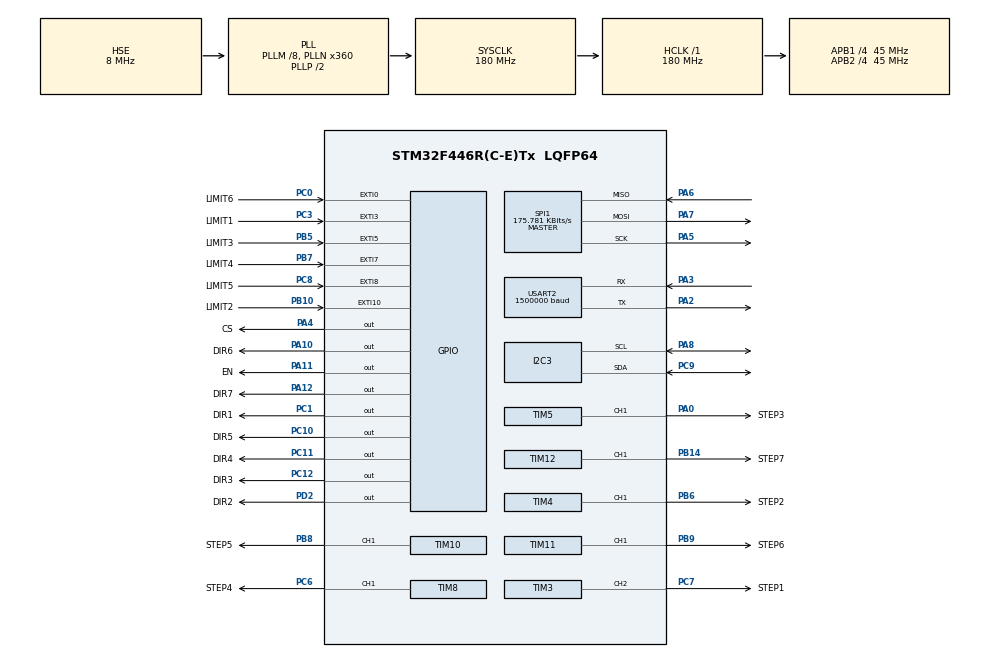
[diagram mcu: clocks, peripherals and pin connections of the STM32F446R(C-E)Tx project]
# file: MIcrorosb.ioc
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Dma.I2C3_RX.2.Direction=DMA_PERIPH_TO_MEMORY
Dma.I2C3_RX.2.FIFOMode=DMA_FIFOMODE_DISABLE
Dma.I2C3_RX.2.Instance=DMA1_Stream1
Dma.I2C3_RX.2.MemDataAlignment=DMA_MDATAALIGN_BYTE
Dma.I2C3_RX.2.MemInc=DMA_MINC_ENABLE
Dma.I2C3_RX.2.Mode=DMA_NORMAL
Dma.I2C3_RX.2.PeriphDataAlignment=DMA_PDATAALIGN_BYTE
Dma.I2C3_RX.2.PeriphInc=DMA_PINC_DISABLE
Dma.I2C3_RX.2.Priority=DMA_PRIORITY_LOW
Dma.I2C3_TX.3.Direction=DMA_MEMORY_TO_PERIPH
Dma.I2C3_TX.3.FIFOMode=DMA_FIFOMODE_DISABLE
Dma.I2C3_TX.3.Instance=DMA1_Stream4
Dma.I2C3_TX.3.MemDataAlignment=DMA_MDATAALIGN_BYTE
Dma.I2C3_TX.3.MemInc=DMA_MINC_ENABLE
Dma.I2C3_TX.3.Mode=DMA_NORMAL
Dma.I2C3_TX.3.PeriphDataAlignment=DMA_PDATAALIGN_BYTE
Dma.I2C3_TX.3.PeriphInc=DMA_PINC_DISABLE
Dma.I2C3_TX.3.Priority=DMA_PRIORITY_LOW
Dma.Request0=USART2_RX
Dma.Request1=USART2_TX
Dma.Request2=I2C3_RX
Dma.Request3=I2C3_TX
Dma.USART2_RX.0.Direction=DMA_PERIPH_TO_MEMORY
Dma.USART2_RX.0.FIFOMode=DMA_FIFOMODE_DISABLE
Dma.USART2_RX.0.Instance=DMA1_Stream5
Dma.USART2_RX.0.MemDataAlignment=DMA_MDATAALIGN_BYTE
Dma.USART2_RX.0.MemInc=DMA_MINC_ENABLE
Dma.USART2_RX.0.Mode=DMA_CIRCULAR
Dma.USART2_RX.0.PeriphDataAlignment=DMA_PDATAALIGN_BYTE
Dma.USART2_RX.0.PeriphInc=DMA_PINC_DISABLE
Dma.USART2_RX.0.Priority=DMA_PRIORITY_VERY_HIGH
Dma.USART2_TX.1.Direction=DMA_MEMORY_TO_PERIPH
Dma.USART2_TX.1.FIFOMode=DMA_FIFOMODE_DISABLE
Dma.USART2_TX.1.Instance=DMA1_Stream6
Dma.USART2_TX.1.MemDataAlignment=DMA_MDATAALIGN_BYTE
Dma.USART2_TX.1.MemInc=DMA_MINC_ENABLE
Dma.USART2_TX.1.Mode=DMA_NORMAL
Dma.USART2_TX.1.PeriphDataAlignment=DMA_PDATAALIGN_BYTE
Dma.USART2_TX.1.PeriphInc=DMA_PINC_DISABLE
Dma.USART2_TX.1.Priority=DMA_PRIORITY_VERY_HIGH
FREERTOS.Tasks01=ros_task,24,3000,StartRosTask,Default,NULL,Dynamic,NULL,NULL;motor_task,8,500,StartMotorTask,Default,NULL,Dynamic,NULL,NULL;sensorread_task,8,500,StartSensorTask,Default,NULL,Dynamic,NULL,NULL
FREERTOS.configMINIMAL_STACK_SIZE=500
FREERTOS.configTOTAL_HEAP_SIZE=32000
I2C3.I2C_Mode=I2C_Fast
Mcu.Family=STM32F4
Mcu.Name=STM32F446R(C-E)Tx
Mcu.Package=LQFP64
NVIC.DMA1_Stream1_IRQn=true\:5\:0\:false\:false\:true\:true\:false\:true\:true
NVIC.DMA1_Stream4_IRQn=true\:5\:0\:false\:false\:true\:true\:false\:true\:true
NVIC.DMA1_Stream5_IRQn=true\:5\:0\:false\:false\:true\:true\:false\:true\:true
NVIC.DMA1_Stream6_IRQn=true\:5\:0\:false\:false\:true\:true\:false\:true\:true
NVIC.EXTI0_IRQn=true\:5\:0\:false\:false\:true\:true\:true\:true\:true
NVIC.EXTI15_10_IRQn=true\:5\:0\:false\:false\:true\:true\:true\:true\:true
NVIC.EXTI3_IRQn=true\:5\:0\:false\:false\:true\:true\:true\:true\:true
NVIC.EXTI9_5_IRQn=true\:5\:0\:false\:false\:true\:true\:true\:true\:true
NVIC.I2C3_ER_IRQn=true\:5\:0\:false\:false\:true\:true\:true\:true\:true
NVIC.I2C3_EV_IRQn=true\:5\:0\:false\:false\:true\:true\:true\:true\:true
NVIC.PriorityGroup=NVIC_PRIORITYGROUP_4
NVIC.TIM1_TRG_COM_TIM11_IRQn=true\:5\:0\:false\:false\:true\:true\:true\:true\:true
NVIC.TIM1_UP_TIM10_IRQn=true\:15\:0\:false\:false\:true\:false\:false\:true\:true
NVIC.TIM3_IRQn=true\:5\:0\:false\:false\:true\:true\:true\:true\:true
NVIC.TIM4_IRQn=true\:5\:0\:false\:false\:true\:true\:true\:true\:true
NVIC.TIM5_IRQn=true\:5\:0\:false\:false\:true\:true\:true\:true\:true
NVIC.TIM7_IRQn=true\:5\:0\:false\:false\:true\:true\:true\:true\:true
NVIC.TIM8_BRK_TIM12_IRQn=true\:5\:0\:false\:false\:true\:true\:true\:true\:true
NVIC.TIM8_UP_TIM13_IRQn=true\:5\:0\:false\:false\:true\:true\:true\:true\:true
NVIC.TimeBase=TIM1_UP_TIM10_IRQn
NVIC.TimeBaseIP=TIM1
NVIC.USART2_IRQn=true\:5\:0\:false\:false\:true\:true\:true\:true\:true
PA0-WKUP.GPIO_Label=STEP3
PA0-WKUP.GPIO_Speed=GPIO_SPEED_FREQ_VERY_HIGH
PA0-WKUP.Signal=S_TIM5_CH1
PA10.GPIO_Label=DIR6
PA10.Signal=GPIO_Output
PA11.GPIO_Label=EN
PA11.Signal=GPIO_Output
PA12.GPIO_Label=DIR7
PA12.Signal=GPIO_Output
PA2.Mode=Asynchronous
PA2.Signal=USART2_TX
PA3.Mode=Asynchronous
PA3.Signal=USART2_RX
PA4.GPIO_Label=CS
PA4.GPIO_Speed=GPIO_SPEED_FREQ_VERY_HIGH
PA4.PinState=GPIO_PIN_SET
PA4.Signal=GPIO_Output
PA5.Mode=Full_Duplex_Master
PA5.Signal=SPI1_SCK
PA6.Mode=Full_Duplex_Master
PA6.Signal=SPI1_MISO
PA7.Mode=Full_Duplex_Master
PA7.Signal=SPI1_MOSI
PA8.GPIO_Pu=GPIO_PULLUP
PA8.Mode=I2C
PA8.Signal=I2C3_SCL
PB10.GPIO_Label=LIMIT2
PB10.GPIO_ModeDefaultEXTI=GPIO_MODE_IT_RISING
PB10.GPIO_PuPd=GPIO_NOPULL
PB10.Signal=GPXTI10
PB14.GPIO_Label=STEP7
PB14.GPIO_Speed=GPIO_SPEED_FREQ_VERY_HIGH
PB14.Signal=S_TIM12_CH1
PB5.GPIO_Label=LIMIT3
PB5.GPIO_ModeDefaultEXTI=GPIO_MODE_IT_RISING
PB5.GPIO_PuPd=GPIO_NOPULL
PB5.Signal=GPXTI5
PB6.GPIO_Label=STEP2
PB6.GPIO_ModeDefaultPP=GPIO_MODE_AF_PP
PB6.GPIO_PuPd=GPIO_PULLDOWN
PB6.GPIO_Speed=GPIO_SPEED_FREQ_VERY_HIGH
PB6.Signal=S_TIM4_CH1
PB7.GPIO_Label=LIMIT4
PB7.GPIO_PuPd=GPIO_PULLDOWN
PB7.Signal=GPXTI7
PB8.GPIO_Label=STEP5
PB8.GPIO_PuPd=GPIO_PULLDOWN
PB8.GPIO_Speed=GPIO_SPEED_FREQ_VERY_HIGH
PB8.Signal=S_TIM10_CH1
PB9.GPIO_Label=STEP6
PB9.GPIO_Speed=GPIO_SPEED_FREQ_VERY_HIGH
PB9.Signal=S_TIM11_CH1
PC0.GPIO_Label=LIMIT6
PC0.GPIO_PuPd=GPIO_PULLDOWN
PC0.Signal=GPXTI0
PC1.GPIO_Label=DIR1
PC1.Signal=GPIO_Output
PC10.GPIO_Label=DIR5
PC10.Signal=GPIO_Output
PC11.GPIO_Label=DIR4
PC11.Signal=GPIO_Output
PC12.GPIO_Label=DIR3
PC12.Signal=GPIO_Output
PC3.GPIO_Label=LIMIT1
PC3.GPIO_PuPd=GPIO_PULLDOWN
PC3.Signal=GPXTI3
PC6.GPIO_Label=STEP4
PC6.GPIO_Speed=GPIO_SPEED_FREQ_VERY_HIGH
PC6.Signal=S_TIM8_CH1
PC7.GPIO_Label=STEP1
PC7.GPIO_Speed=GPIO_SPEED_FREQ_VERY_HIGH
PC7.Signal=S_TIM3_CH2
PC8.GPIO_Label=LIMIT5
PC8.GPIO_ModeDefaultEXTI=GPIO_MODE_IT_RISING
PC8.GPIO_PuPd=GPIO_NOPULL
PC8.Signal=GPXTI8
PC9.GPIO_Pu=GPIO_PULLUP
PC9.Mode=I2C
PC9.Signal=I2C3_SDA
PD2.GPIO_Label=DIR2
PD2.Signal=GPIO_Output
PH0-OSC_IN.Mode=HSE-External-Oscillator
PH0-OSC_IN.Signal=RCC_OSC_IN
PH1-OSC_OUT.Mode=HSE-External-Oscillator
PH1-OSC_OUT.Signal=RCC_OSC_OUT
ProjectManager.HeapSize=0x200
ProjectManager.StackSize=0x400
ProjectManager.TargetToolchain=STM32CubeIDE
RCC.AHBFreq_Value=180000000
RCC.APB1CLKDivider=RCC_HCLK_DIV4
RCC.APB1Freq_Value=45000000
RCC.APB1TimFreq_Value=90000000
RCC.APB2CLKDivider=RCC_HCLK_DIV4
RCC.APB2Freq_Value=45000000
RCC.APB2TimFreq_Value=90000000
RCC.CortexFreq_Value=180000000
RCC.HCLKFreq_Value=180000000
RCC.HSE_VALUE=8000000
RCC.PLLM=8
RCC.PLLN=360
RCC.PLLSourceVirtual=RCC_PLLSOURCE_HSE
RCC.SYSCLKFreq_VALUE=180000000
RCC.SYSCLKSource=RCC_SYSCLKSOURCE_PLLCLK
RCC.USBFreq_Value=180000000
RCC.VCOOutputFreq_Value=360000000
SH.S_TIM10_CH1.0=TIM10_CH1,PWM Generation1 CH1
SH.S_TIM11_CH1.0=TIM11_CH1,PWM Generation1 CH1
SH.S_TIM12_CH1.0=TIM12_CH1,PWM Generation1 CH1
SH.S_TIM3_CH2.0=TIM3_CH2,PWM Generation2 CH2
SH.S_TIM4_CH1.0=TIM4_CH1,PWM Generation1 CH1
SH.S_TIM5_CH1.0=TIM5_CH1,PWM Generation1 CH1
SH.S_TIM8_CH1.0=TIM8_CH1,PWM Generation1 CH1
SPI1.BaudRatePrescaler=SPI_BAUDRATEPRESCALER_256
SPI1.CalculateBaudRate=175.781 KBits/s
SPI1.Direction=SPI_DIRECTION_2LINES
SPI1.Mode=SPI_MODE_MASTER
SPI1.VirtualType=VM_MASTER
TIM10.AutoReloadPreload=TIM_AUTORELOAD_PRELOAD_ENABLE
TIM10.Channel=TIM_CHANNEL_1
TIM10.ClockDivision=TIM_CLOCKDIVISION_DIV1
TIM10.OCFastMode_PWM=TIM_OCFAST_DISABLE
TIM10.Period=999
TIM10.Prescaler=44
TIM11.AutoReloadPreload=TIM_AUTORELOAD_PRELOAD_ENABLE
TIM11.Channel=TIM_CHANNEL_1
TIM11.ClockDivision=TIM_CLOCKDIVISION_DIV1
TIM11.OCFastMode_PWM=TIM_OCFAST_DISABLE
TIM11.Period=999
TIM11.Prescaler=44
TIM12.AutoReloadPreload=TIM_AUTORELOAD_PRELOAD_ENABLE
TIM12.Channel-PWM\ Generation1\ CH1=TIM_CHANNEL_1
TIM12.ClockDivision=TIM_CLOCKDIVISION_DIV1
TIM12.OCFastMode_PWM-PWM\ Generation1\ CH1=TIM_OCFAST_ENABLE
TIM12.Period=999
TIM12.Prescaler=44
TIM3.AutoReloadPreload=TIM_AUTORELOAD_PRELOAD_ENABLE
TIM3.Channel-PWM\ Generation2\ CH2=TIM_CHANNEL_2
TIM3.OC2Preload_PWM=ENABLE
TIM3.OCFastMode_PWM-PWM\ Generation2\ CH2=TIM_OCFAST_ENABLE
TIM3.Period=999
TIM3.Prescaler=44
TIM3.Pulse-PWM\ Generation2\ CH2=0
TIM4.AutoReloadPreload=TIM_AUTORELOAD_PRELOAD_ENABLE
TIM4.Channel-PWM\ Generation1\ CH1=TIM_CHANNEL_1
TIM4.OCFastMode_PWM-PWM\ Generation1\ CH1=TIM_OCFAST_ENABLE
TIM4.Period=89
TIM4.Prescaler=44
TIM4.Pulse-PWM\ Generation1\ CH1=10
TIM5.AutoReloadPreload=TIM_AUTORELOAD_PRELOAD_ENABLE
TIM5.Channel-PWM\ Generation1\ CH1=TIM_CHANNEL_1
TIM5.Period=999
TIM5.Prescaler=44
TIM7.Period=49
TIM7.Prescaler=89
TIM8.AutoReloadPreload=TIM_AUTORELOAD_PRELOAD_ENABLE
TIM8.Channel-PWM\ Generation1\ CH1=TIM_CHANNEL_1
TIM8.ClockDivision=TIM_CLOCKDIVISION_DIV1
TIM8.OCFastMode_PWM-PWM\ Generation1\ CH1=TIM_OCFAST_DISABLE
TIM8.Period=999
TIM8.Prescaler=44
USART2.BaudRate=1500000
USART2.OverSampling=UART_OVERSAMPLING_16
USART2.VirtualMode=VM_ASYNC
VP_FREERTOS_VS_CMSIS_V2.Mode=CMSIS_V2
VP_SYS_VS_tim1.Mode=TIM1
VP_TIM10_VS_ClockSourceINT.Mode=Enable_Timer
VP_TIM11_VS_ClockSourceINT.Mode=Enable_Timer
VP_TIM7_VS_ClockSourceINT.Mode=Enable_Timer
board=custom

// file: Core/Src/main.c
/* USER CODE BEGIN Header */
/**
 ******************************************************************************
 * @file           : main.c
 * @brief          : Main program body
 ******************************************************************************
 * @attention
 *
 * Copyright (c) 2025 STMicroelectronics.
 * All rights reserved.
 *
 * This software is licensed under terms that can be found in the LICENSE file
 * in the root directory of this software component.
 * If no LICENSE file comes with this software, it is provided AS-IS.
 *
 ******************************************************************************
 */
/* USER CODE END Header */
#include "main.h"
#include "cmsis_os.h"
#include "dma.h"
#include "i2c.h"
#include "spi.h"
#include "tim.h"
#include "usart.h"
#include "gpio.h"

void SystemClock_Config(void);
void MX_FREERTOS_Init(void);
/* USER CODE BEGIN PFP */
void MotorTimerISR(TIM_HandleTypeDef *htim);
/* USER CODE END PFP */

/* USER CODE BEGIN 0 */

/* --- Minimal transport --- */
/* USER CODE END 0 */

int main(void)
{

  /* MCU Configuration--------------------------------------------------------*/

  /* Reset of all peripherals, Initializes the Flash interface and the Systick. */
  HAL_Init();

  /* Configure the system clock */
  SystemClock_Config();

  /* Initialize all configured peripherals */
  MX_GPIO_Init();
  MX_DMA_Init();
  MX_USART2_UART_Init();
  MX_SPI1_Init();
  MX_TIM4_Init();
  MX_TIM5_Init();
  MX_TIM8_Init();
  MX_TIM10_Init();
  MX_TIM11_Init();
  MX_TIM12_Init();
  MX_I2C3_Init();
  MX_TIM3_Init();
  MX_TIM7_Init();
  /* USER CODE BEGIN 2 */
  HAL_GPIO_WritePin(EN_GPIO_Port, EN_Pin, 0);

  /* Start S-curve tick timer (runs at 20kHz indefinitely) */
  extern void SCurve_Tick_Start(void);
  SCurve_Tick_Start();
  /* USER CODE END 2 */

  /* Init scheduler */
  osKernelInitialize();  /* Call init function for freertos objects (in cmsis_os2.c) */
  MX_FREERTOS_Init();

  /* Start scheduler */
  osKernelStart();

  /* We should never get here as control is now taken by the scheduler */

  /* Infinite loop */
  while (1) {

  }
}

void SystemClock_Config(void)
{
  RCC_OscInitTypeDef RCC_OscInitStruct = {0};
  RCC_ClkInitTypeDef RCC_ClkInitStruct = {0};

  /** Configure the main internal regulator output voltage
  */
  __HAL_RCC_PWR_CLK_ENABLE();
  __HAL_PWR_VOLTAGESCALING_CONFIG(PWR_REGULATOR_VOLTAGE_SCALE1);

  /** Initializes the RCC Oscillators according to the specified parameters
  * in the RCC_OscInitTypeDef structure.
  */
  RCC_OscInitStruct.OscillatorType = RCC_OSCILLATORTYPE_HSE;
  RCC_OscInitStruct.HSEState = RCC_HSE_ON;
  RCC_OscInitStruct.PLL.PLLState = RCC_PLL_ON;
  RCC_OscInitStruct.PLL.PLLSource = RCC_PLLSOURCE_HSE;
  RCC_OscInitStruct.PLL.PLLM = 8;
  RCC_OscInitStruct.PLL.PLLN = 360;
  RCC_OscInitStruct.PLL.PLLP = RCC_PLLP_DIV2;
  RCC_OscInitStruct.PLL.PLLQ = 2;
  RCC_OscInitStruct.PLL.PLLR = 2;
  if (HAL_RCC_OscConfig(&RCC_OscInitStruct) != HAL_OK)
  {
    Error_Handler();
  }

  /** Activate the Over-Drive mode
  */
  if (HAL_PWREx_EnableOverDrive() != HAL_OK)
  {
    Error_Handler();
  }

  /** Initializes the CPU, AHB and APB buses clocks
  */
  RCC_ClkInitStruct.ClockType = RCC_CLOCKTYPE_HCLK|RCC_CLOCKTYPE_SYSCLK
                              |RCC_CLOCKTYPE_PCLK1|RCC_CLOCKTYPE_PCLK2;
  RCC_ClkInitStruct.SYSCLKSource = RCC_SYSCLKSOURCE_PLLCLK;
  RCC_ClkInitStruct.AHBCLKDivider = RCC_SYSCLK_DIV1;
  RCC_ClkInitStruct.APB1CLKDivider = RCC_HCLK_DIV4;
  RCC_ClkInitStruct.APB2CLKDivider = RCC_HCLK_DIV4;

  if (HAL_RCC_ClockConfig(&RCC_ClkInitStruct, FLASH_LATENCY_5) != HAL_OK)
  {
    Error_Handler();
  }
}

void HAL_TIM_PeriodElapsedCallback(TIM_HandleTypeDef *htim)
{
  if (htim->Instance == TIM1)
  {
    HAL_IncTick();
  }
  /* USER CODE BEGIN Callback 1 */
  else {
    MotorTimerISR(htim);
  }
  /* USER CODE END Callback 1 */
}

void Error_Handler(void)
{
  __disable_irq();
  while (1) {
  }
}
#ifdef USE_FULL_ASSERT
/**
  * @brief  Reports the name of the source file and the source line number
  *         where the assert_param error has occurred.
  * @param  file: pointer to the source file name
  * @param  line: assert_param error line source number
  * @retval None
  */
void assert_failed(uint8_t *file, uint32_t line)
{
  /* USER CODE BEGIN 6 */
  /* User can add his own implementation to report the file name and line
     number, ex: printf("Wrong parameters value: file %s on line %d\r\n", file,
     line) */
  /* USER CODE END 6 */
}
#endif /* USE_FULL_ASSERT */

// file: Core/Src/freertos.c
/* USER CODE BEGIN Header */
/**
  ******************************************************************************
  * File Name          : freertos.c
  * Description        : Code for freertos applications
  ******************************************************************************
  * @attention
  *
  * Copyright (c) 2025 STMicroelectronics.
  * All rights reserved.
  *
  * This software is licensed under terms that can be found in the LICENSE file
  * in the root directory of this software component.
  * If no LICENSE file comes with this software, it is provided AS-IS.
  *
  ******************************************************************************
  */
/* USER CODE END Header */

#include "FreeRTOS.h"
#include "task.h"
#include "main.h"
#include "cmsis_os.h"

/* USER CODE BEGIN Includes */
#include "uart_task.h"
#include "motorcontrol_task.h"
/* USER CODE END Includes */

/* USER CODE BEGIN Variables */
osSemaphoreId_t uartInitSemaphore;
osSemaphoreId_t i2cDmaSemaphore;

/* USER CODE END Variables */
/* Definitions for ros_task */
osThreadId_t uart_taskHandle;
const osThreadAttr_t uart_task_attributes = {
  .name = "uart_task",
  .stack_size = 3000 * 4,
  .priority = (osPriority_t) osPriorityNormal,
};

/* Definitions for sensorread_task */
osThreadId_t sensorread_taskHandle;
const osThreadAttr_t sensorread_task_attributes = {
  .name = "sensorread_task",
  .stack_size = 500 * 4,
  .priority = (osPriority_t) osPriorityLow,
};

void StartUartTask(void *argument);
void StartSensorTask(void *argument);

void MX_FREERTOS_Init(void); /* (MISRA C 2004 rule 8.1) */

void MX_FREERTOS_Init(void) {

  /* USER CODE BEGIN RTOS_SEMAPHORES */
  /* add semaphores, ... */
  uartInitSemaphore = osSemaphoreNew(1, 0, NULL);
  i2cDmaSemaphore = osSemaphoreNew(1, 0, NULL);
  /* USER CODE END RTOS_SEMAPHORES */

  /* Create the thread(s) */
  /* creation of ros_task */
  uart_taskHandle = osThreadNew(StartUartTask, NULL, &uart_task_attributes);

  /* creation of motor_task */

  /* creation of sensorread_task */
  sensorread_taskHandle = osThreadNew(StartSensorTask, NULL, &sensorread_task_attributes);

}
